VERSION ""

NS_ :

BS_:

BU_:

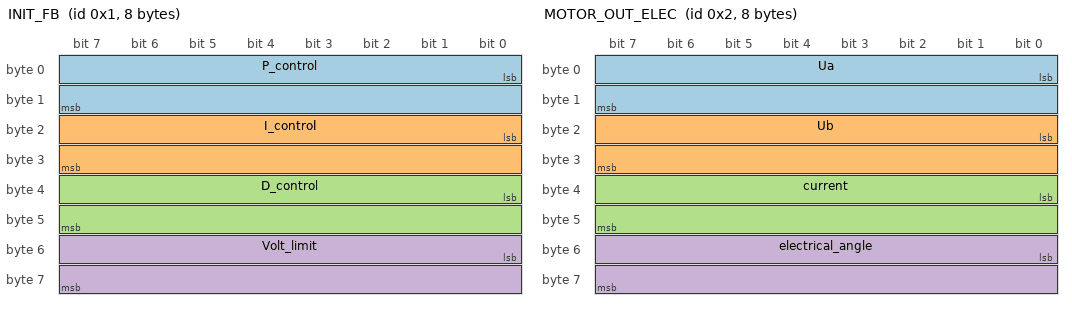
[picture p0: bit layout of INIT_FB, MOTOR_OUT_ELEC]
BO_ 1 INIT_FB: 8 Vector__XXX
	SG_ P_control : 0|16@1- (0.125,0) [0|8192] "" Vector__XXX
	SG_ I_control : 16|16@1- (0.125,0) [0|8192] "" Vector__XXX
	SG_ D_control : 32|16@1- (0.125,0) [0|8192] "" Vector__XXX
	SG_ Volt_limit : 48|16@1- (0.125,-4095) [-4096|4096] "" Vector__XXX

BO_ 2 MOTOR_OUT_ELEC: 8 Vector__XXX
	SG_ Ua : 0|16@1- (0.125,-4095) [-4096|4096] "" Vector__XXX
	SG_ Ub : 16|16@1- (0.125,-4095) [-4096|4096] "" Vector__XXX
	SG_ current : 32|16@1- (0.125,-4095) [-4096|4096] "" Vector__XXX
	SG_ electrical_angle : 48|16@1- (0.125,-4095) [-4096|4096] "" Vector__XXX

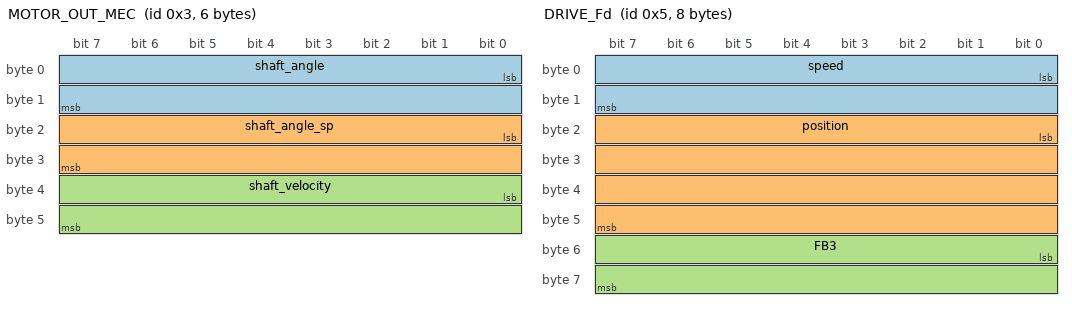
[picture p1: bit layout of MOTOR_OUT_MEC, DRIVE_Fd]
BO_ 3 MOTOR_OUT_MEC: 6 Vector__XXX
	SG_ shaft_angle : 0|16@1- (0.125,-4095) [-4096|4096] "" Vector__XXX
	SG_ shaft_angle_sp : 16|16@1- (0.125,-4095) [-4096|4096] "" Vector__XXX
	SG_ shaft_velocity : 32|16@1- (0.125,-4095) [-4096|4096] "" Vector__XXX

BO_ 7 MOTOR_ANGLE_SP: 2 Vector__XXX
	SG_ angle_sp : 0|16@1+ (0.125,-4095) [-4096|4096] "" Vector__XXX

BO_ 5 DRIVE_Fd: 8 Vector__XXX
	SG_ speed : 0|16@1- (1,0) [0|0] "" Vector__XXX
	SG_ position : 16|32@1- (1,0) [0|0] "" Vector__XXX
	SG_ FB3 : 48|16@1- (1,0) [0|0] "" Vector__XXX

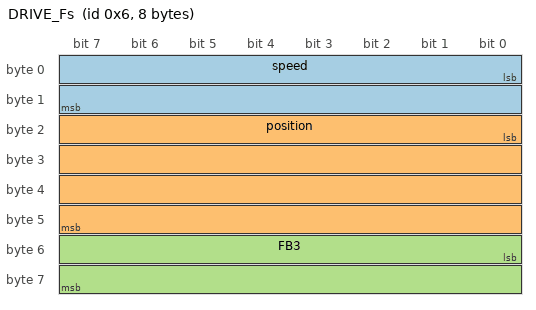
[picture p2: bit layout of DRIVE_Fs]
BO_ 6 DRIVE_Fs: 8 Vector__XXX
	SG_ speed : 0|16@1- (1,0) [0|0] "" Vector__XXX
	SG_ position : 16|32@1- (1,0) [0|0] "" Vector__XXX
	SG_ FB3 : 48|16@1- (1,0) [0|0] "" Vector__XXX

CM_ BO_ 933 "Driver controller set point";
CM_ SG_ 933 speed_sp "Driver speed set point";
CM_ BO_ 934 "Steering controller set point";
CM_ SG_ 934 speed_sp "Steer speed set point";
CM_ BO_ 421 "Driver controller feedback";
CM_ BO_ 422 "Steer controller feedback";
CM_ BO_ 293 "Driver controller feedback 2";
CM_ BO_ 294 "Steer controller feedback 2";

BA_DEF_ BO_  "VFrameFormat" ENUM  "StandardCAN","ExtendedCAN","reserved","J1939PG";
BA_DEF_  "DatabaseVersion" STRING ;
BA_DEF_  "BusType" STRING ;
BA_DEF_  "ProtocolType" STRING ;
BA_DEF_  "DatabaseCompiler" STRING ;
BA_DEF_DEF_  "VFrameFormat" "J1939PG";
BA_DEF_DEF_  "DatabaseVersion" "DEMO PLUS";
BA_DEF_DEF_  "BusType" "";
BA_DEF_DEF_  "ProtocolType" "";
BA_DEF_DEF_  "DatabaseCompiler" "";
BA_ "ProtocolType" "J1939";
BA_ "BusType" "CAN";
BA_ "DatabaseCompiler" "CSS ELECTRONICS (WWW.CSSELECTRONICS.COM)";
BA_ "DatabaseVersion" "1.0.0";
